# max32660 register map
Vendor: Maxim Integrated; Series: ARMCM4; File version: 1.0
CPU: CM4 r2p1, little endian, MPU, FPU, 3 interrupt priority bits
Registers are 32-bit, read-write, reset 0x0 unless marked. A register's access mark holds for its fields unless they carry their own. Offsets are from the block's base; [hi:lo] are bit positions; 'fields as' and 'values as' point back to an identical list.

## SIR — System Initialization Registers.
Base 0x40000400
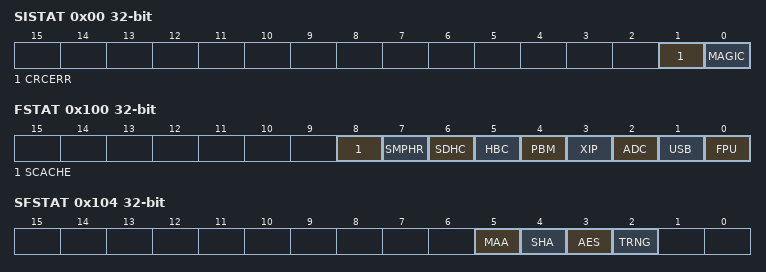
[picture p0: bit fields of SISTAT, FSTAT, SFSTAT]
0x00 SISTAT ro — System Initialization Status Register.
  [1] CRCERR — CRC Error Status. This bit is set by the system initialization block following power-up.
    on read: 0=noError (No CRC errors occurred during the read of the OTP memory block.); 1=error (A CRC error occurred while reading the OTP. The address of the failure location in the OTP memory is stored in the ERRADDR register.)
  [0] MAGIC — Magic Word Validation. This bit is set by the system initialization block following power-up.
    on read: 0=magicNotSet (Magic word was not set (OTP has not been initialized properly).); 1=magicSet (Magic word was set (OTP contains valid settings).)
0x04 ERRADDR ro — Read-only field set by the SIB block if a CRC error occurs during the read of the OTP memory. Contains the failing address in OTP memory (when CRCERR equals 1).
0x100 FSTAT ro — funcstat register.
  [all] fields
    0=no; 1=yes
  [8] SCACHE — System Cache function.
  [7] SMPHR — SMPHR function.
  [6] SDHC — SDHC function.
  [5] HBC — HBC function.
  [4] PBM — PBM function.
  [3] XIP — XiP function.
  [2] ADC — 10-bit Sigma Delta ADC.
  [1] USB — USB Device.
  [0] FPU — FPU Function.
0x104 SFSTAT ro — secfuncstat register.
  [all] fields
    0=no; 1=yes
  [5] MAA — MAA function.
  [4] SHA — SHA function.
  [3] AES — AES function.
  [2] TRNG — TRNG function.

## TMR0 — 32-bit reloadable timer that can be used for timing and event counting.
Base 0x40010000
Same registers: TMR1 0x40011000, TMR2 0x40012000
0x00 CNT reset 0x1 — Count. This register stores the current timer count.
0x04 CMP reset 0xFFFF — Compare. This register stores the compare value, which is used to set the maximum count value to initiate a reload of the timer to 0x0001.
0x08 PWM — PWM. This register stores the value that is compared to the current timer count.
0x0C INTR write-1-clears — Clear Interrupt. Writing a value (0 or 1) to a bit in this register clears the associated interrupt.
  [0] IRQ_CLR — Clear Interrupt.
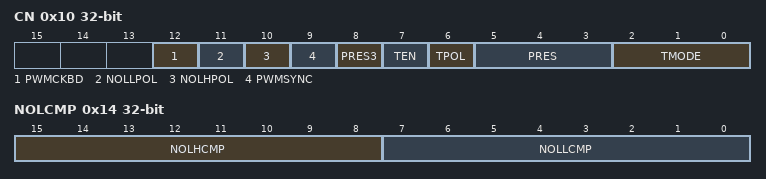
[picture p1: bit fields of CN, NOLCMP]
0x10 CN — Timer Control Register.
  [12] PWMCKBD — Timer PWM output 0A Mode Disable.
    1=dis (Disable.); 0=en (Enable.)
  [11] NOLLPOL — Timer PWM output 0A' polarity bit.
    0=dis (Disable.); 1=en (Enable.)
  [10] NOLHPOL — Timer PWM output 0A polarity bit.
    0=dis (Disable.); 1=en (Enable.)
  [9] PWMSYNC — Timer PWM Synchronization Mode Enable.
    0=dis (Disable.); 1=en (Enable.)
  [8] PRES3 — MSB of prescaler value.
  [7] TEN — Timer Enable.
    0=dis (Disable.); 1=en (Enable.)
  [6] TPOL — Timer input/output polarity bit.
    0=Active High; 1=Active Low
  [5:3] PRES — Prescaler. Set the Timer's prescaler value. The prescaler divides the PCLK input to the timer and sets the Timer's Count Clock, F_CNT_CLK = PCLK(HZ)/prescaler. The Timer's prescaler setting is a 4-bit value with pres3:pres[2:0].
    0=div1 (Divide by 1.); 1=div2 (Divide by 2.); 2=div4 (Divide by 4.); 3=div8 (Divide by 8.); 4=div16 (Divide by 16.); 5=div32 (Divide by 32.); 6=div64 (Divide by 64.); 7=div128 (Divide by 128.)
  [2:0] TMODE — Timer Mode.
    0=One Shot Mode; 1=Continuous Mode; 2=Counter Mode; 3=pwm (PWM Mode.); 4=Capture Mode; 5=Compare Mode; 6=Gated Mode; 7=Capture/Compare Mode
0x14 NOLCMP — Timer Non-Overlapping Compare Register.
  [15:8] NOLHCMP — Non-overlapping High Compare. The 8-bit timer count value of non-overlapping time between falling edge of PWM output 0A' and next rising edge of PWM output 0A.
  [7:0] NOLLCMP — Non-overlapping Low Compare. The 8-bit timer count value of non-overlapping time between falling edge of PWM output 0A and next rising edge of PWM output 0A'.

## WDT0 — Watchdog Timer 0
Base 0x40003000
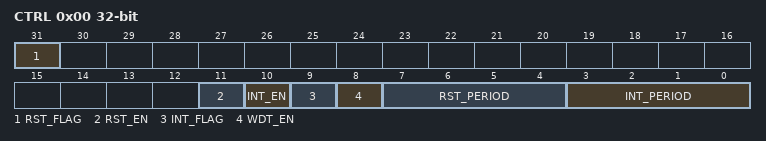
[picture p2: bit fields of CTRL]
0x00 CTRL (reset mask 0x7FFFF000) — Watchdog Timer Control Register.
  [31] RST_FLAG — Watchdog Timer Reset Flag.
    0=noEvent (The event has not occurred.); 1=occurred (The event has occurred.)
  [11] RST_EN — Watchdog Timer Reset Enable.
    0=dis (Disable.); 1=en (Enable.)
  [10] INT_EN — Watchdog Timer Interrupt Enable.
    0=dis (Disable.); 1=en (Enable.)
  [9] INT_FLAG write-1-clears — Watchdog Timer Interrupt Flag.
    0=inactive (No interrupt is pending.); 1=pending (An interrupt is pending.)
  [8] WDT_EN — Watchdog Timer Enable.
    0=dis (Disable.); 1=en (Enable.)
  [7:4] RST_PERIOD — Watchdog Reset Period. The watchdog timer will assert a reset, if enabled, if the CPU does not write the watchdog reset sequence to the WDT_RST register before the watchdog timer has counted this time period since the last timer reset.
    0=wdt2pow31 (2**31 clock cycles.); 1=wdt2pow30 (2**30 clock cycles.); 2=wdt2pow29 (2**29 clock cycles.); 3=wdt2pow28 (2**28 clock cycles.); 4=wdt2pow27 (2^27 clock cycles.); 5=wdt2pow26 (2**26 clock cycles.); 6=wdt2pow25 (2**25 clock cycles.); 7=wdt2pow24 (2**24 clock cycles.); 8=wdt2pow23 (2**23 clock cycles.); 9=wdt2pow22 (2**22 clock cycles.); 10=wdt2pow21 (2**21 clock cycles.); 11=wdt2pow20 (2**20 clock cycles.); 12=wdt2pow19 (2**19 clock cycles.); 13=wdt2pow18 (2**18 clock cycles.); 14=wdt2pow17 (2**17 clock cycles.); 15=wdt2pow16 (2**16 clock cycles.)
  [3:0] INT_PERIOD — Watchdog Interrupt Period. The watchdog timer will assert an interrupt, if enabled, if the CPU does not write the watchdog reset sequence to the WDT_RST register before the watchdog timer has counted this time period since the last timer reset.
    values as RST_PERIOD
0x04 RST wo — Watchdog Timer Reset Register.
  [7:0] WDT_RST — Writing the watchdog counter 'reset sequence' to this register resets the watchdog counter. If the watchdog count exceeds INT_PERIOD then a watchdog interrupt will occur, if enabled. If the watchdog count exceeds RST_PERIOD then a watchdog reset will occur, if enabled.
    165=seq0 (The first value to be written to reset the WDT.); 90=seq1 (The second value to be written to reset the WDT.)
